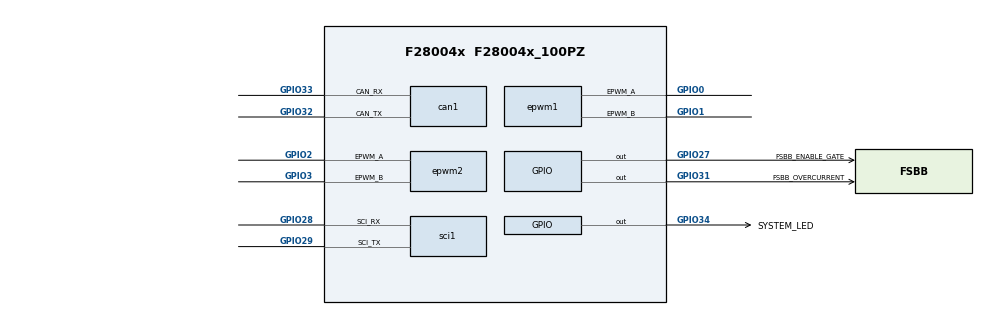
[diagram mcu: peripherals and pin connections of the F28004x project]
/**
 * @cliArgs --device "F28004x" --part "F28004x_100PZ" --package "F28004x_100PZ" --context "system" --product "gmp_pro@1.00.00.05" --product "C2000WARE@5.04.00.00"
 * @versions {"tool":"1.21.0+3721"}
 */

/**
 * Import the modules used in this configuration.
 */
const adc              = scripting.addModule("/driverlib/adc.js", {}, false);
const adc1             = adc.addInstance();
const adc2             = adc.addInstance();
const adc3             = adc.addInstance();
const asysctl          = scripting.addModule("/driverlib/asysctl.js");
const can              = scripting.addModule("/driverlib/can.js", {}, false);
const can1             = can.addInstance();
const device_support   = scripting.addModule("/driverlib/device_support.js");
const epwm             = scripting.addModule("/driverlib/epwm.js", {}, false);
const epwm1            = epwm.addInstance();
const epwm2            = epwm.addInstance();
const gpio             = scripting.addModule("/driverlib/gpio.js", {}, false);
const gpio1            = gpio.addInstance();
const gpio2            = gpio.addInstance();
const gpio3            = gpio.addInstance();
const inputxbar        = scripting.addModule("/driverlib/inputxbar.js", {}, false);
const inputxbar1       = inputxbar.addInstance();
const inputxbar_input  = scripting.addModule("/driverlib/inputxbar_input.js");
const inputxbar_input1 = inputxbar_input.addInstance();
const sci              = scripting.addModule("/driverlib/sci.js", {}, false);
const sci1             = sci.addInstance();

/**
 * Write custom configuration values to the imported modules.
 */
adc1.$name                    = "FSBB_IL_ADC";
adc1.adcClockPrescaler        = "ADC_CLK_DIV_2_0";
adc1.interruptPulseMode       = "ADC_PULSE_END_OF_CONV";
adc1.enabledSOCs              = ["ADC_SOC_NUMBER0"];
adc1.soc0Channel              = "ADC_CH_ADCIN6";
adc1.soc0SampleWindow         = 64;
adc1.soc0Trigger              = "ADC_TRIGGER_EPWM1_SOCA";
adc1.enabledInts              = ["ADC_INT_NUMBER1"];
adc1.enableInterrupt1         = true;
adc1.registerInterrupts       = ["1"];
adc1.adcInt1.enableInterrupt  = true;
adc1.adcInt1.interruptHandler = "MainISR";

adc2.$name              = "FSBB_VIN_ADC";
adc2.adcBase            = "ADCB_BASE";
adc2.adcClockPrescaler  = "ADC_CLK_DIV_2_0";
adc2.interruptPulseMode = "ADC_PULSE_END_OF_CONV";
adc2.enabledSOCs        = ["ADC_SOC_NUMBER0"];
adc2.soc0SampleWindow   = 32;
adc2.soc0Trigger        = "ADC_TRIGGER_EPWM1_SOCA";

adc3.$name              = "FSBB_VOUT_ADC";
adc3.adcBase            = "ADCC_BASE";
adc3.adcClockPrescaler  = "ADC_CLK_DIV_2_0";
adc3.interruptPulseMode = "ADC_PULSE_END_OF_CONV";
adc3.enabledSOCs        = ["ADC_SOC_NUMBER0"];
adc3.soc0Channel        = "ADC_CH_ADCIN1";
adc3.soc0SampleWindow   = 32;
adc3.soc0Trigger        = "ADC_TRIGGER_EPWM1_SOCA";

asysctl.analogReferenceVoltage = "1P65";

can1.$name                 = "LAUNCHXL_CAN";
can1.enableInterrupt       = true;
can1.registerInterrupts    = true;
can1.interruptFlags        = ["CAN_INT_IE0"];
can1.interruptLine         = ["CAN_GLOBAL_INT_CANINT0"];
can1.msgObjsUsed           = [1,2,4,5,6,7];
can1.can.$assign           = "CANA";
can1.can.can_rxPin.$assign = "GPIO33";
can1.can.can_txPin.$assign = "GPIO32";
can1.msgObj1.$name         = "msgObj0";
can1.msgObj1.msgID         = 257;
can1.msgObj1.flags         = ["CAN_MSG_OBJ_RX_INT_ENABLE"];
can1.msgObj2.$name         = "msgObj1";
can1.msgObj2.msgID         = 258;
can1.msgObj2.flags         = ["CAN_MSG_OBJ_RX_INT_ENABLE"];
can1.msgObj4.$name         = "msgObj2";
can1.msgObj4.msgID         = 513;
can1.msgObj4.msgType       = "CAN_MSG_OBJ_TYPE_TX";
can1.msgObj4.msgLen        = 8;
can1.msgObj5.$name         = "msgObj3";
can1.msgObj5.msgID         = 514;
can1.msgObj5.msgType       = "CAN_MSG_OBJ_TYPE_TX";
can1.msgObj5.msgLen        = 8;
can1.msgObj6.$name         = "msgObj4";
can1.msgObj6.msgID         = 515;
can1.msgObj6.msgType       = "CAN_MSG_OBJ_TYPE_TX";
can1.msgObj6.msgLen        = 8;
can1.msgObj7.$name         = "msgObj5";
can1.msgObj7.msgID         = 516;
can1.msgObj7.msgType       = "CAN_MSG_OBJ_TYPE_TX";
can1.msgObj7.msgLen        = 8;

const multiplier2         = system.clockTree["PLL_IMULT"];
multiplier2.multiplyValue = 10;

const mux2       = system.clockTree["OSCCLKSRCSEL"];
mux2.inputSelect = "X1_XTAL";

device_support.useStandardCodeStartBranch = false;

epwm1.$name                                             = "FSBB_BUCK_PWM";
epwm1.epwmTimebase_counterMode                          = "EPWM_COUNTER_MODE_UP_DOWN";
epwm1.epwmTimebase_hsClockDiv                           = "EPWM_HSCLOCK_DIVIDER_1";
epwm1.epwmTripZone_oneShotSource                        = ["EPWM_TZ_SIGNAL_OSHT1"];
epwm1.epwmTripZone_EPWM_TZ_ACTION_EVENT_TZA             = "EPWM_TZ_ACTION_LOW";
epwm1.epwmTripZone_EPWM_TZ_ACTION_EVENT_TZB             = "EPWM_TZ_ACTION_LOW";
epwm1.epwmTimebase_syncOutPulseMode                     = "EPWM_SYNC_OUT_PULSE_ON_COUNTER_ZERO";
epwm1.epwmEventTrigger_EPWM_SOC_A_triggerEnable         = true;
epwm1.epwmEventTrigger_EPWM_SOC_A_triggerSource         = "EPWM_SOC_TBCTR_ZERO";
epwm1.epwmEventTrigger_EPWM_SOC_A_triggerEventPrescalar = "1";
epwm1.epwm.$assign                                      = "EPWM1";
epwm1.epwm.epwm_aPin.$assign                            = "GPIO0";
epwm1.epwm.epwm_bPin.$assign                            = "GPIO1";

epwm2.$name                                 = "FSBB_BOOST_PWM";
epwm2.epwmTimebase_counterMode              = "EPWM_COUNTER_MODE_UP_DOWN";
epwm2.epwmTimebase_hsClockDiv               = "EPWM_HSCLOCK_DIVIDER_1";
epwm2.epwmTripZone_oneShotSource            = ["EPWM_TZ_SIGNAL_OSHT1"];
epwm2.epwmTripZone_EPWM_TZ_ACTION_EVENT_TZA = "EPWM_TZ_ACTION_LOW";
epwm2.epwmTripZone_EPWM_TZ_ACTION_EVENT_TZB = "EPWM_TZ_ACTION_LOW";
epwm2.epwmTimebase_phaseEnable              = true;
epwm2.epwmTimebase_counterModeAfterSync     = "EPWM_COUNT_MODE_UP_AFTER_SYNC";
epwm2.epwm.$assign                          = "EPWM2";
epwm2.epwm.epwm_aPin.$assign                = "GPIO2";
epwm2.epwm.epwm_bPin.$assign                = "GPIO3";

gpio1.$name             = "FSBB_ENABLE_GATE";
gpio1.direction         = "GPIO_DIR_MODE_OUT";
gpio1.writeInitialValue = true;
gpio1.gpioPin.$assign   = "GPIO27";

gpio2.$name           = "FSBB_OVERCURRENT";
gpio2.qualMode        = "GPIO_QUAL_ASYNC";
gpio2.gpioPin.$assign = "GPIO31";

gpio3.$name             = "SYSTEM_LED";
gpio3.direction         = "GPIO_DIR_MODE_OUT";
gpio3.writeInitialValue = true;
gpio3.initialValue      = 1;
gpio3.gpioPin.$assign   = "GPIO34";

inputxbar1.$name = "FSBB_TRIP_INPUT";

inputxbar_input1.$name         = "myINPUTXBARINPUT0";
inputxbar_input1.inputxbarGpio = "GPIO31";

sci1.$name                      = "LAUNCHXL_UART_USB";
sci1.selectRegisteredInterrupts = ["registerRxInt"];
sci1.enabledFIFOInterrupts      = ["SCI_INT_RXFF"];
sci1.enabledErrorInterrupts     = ["SCI_INT_FE","SCI_INT_OE"];
sci1.rxFifo                     = "SCI_FIFO_RX14";
sci1.sci.$assign                = "SCIA";
sci1.sci.sci_rxPin.$assign      = "GPIO28";
sci1.sci.sci_txPin.$assign      = "GPIO29";
sci1.rxQual.$name               = "myGPIOQUAL0";
sci1.txQual.$name               = "myGPIOQUAL1";
sci1.sciRXInt.enableInterrupt   = true;
